# MSP430FR6972 register map
Registers are 16-bit, read-write, reset 0x0 unless marked. A register's access mark holds for its fields unless they carry their own. Offsets are from the block's base; [hi:lo] are bit positions; {n}, {i} and the like mark numbered series.

## USCI_A0_SPI_MODE
Base 0x000005C0
0x00 UCA0CTL1_SPI 8-bit — USCI A0 Control Register 1
0x01 UCA0CTL0_SPI 8-bit — USCI A0 Control Register 0
0x06 UCA0BR0_SPI 8-bit — USCI A0 Baud Rate 0
0x07 UCA0BR1_SPI 8-bit — USCI A0 Baud Rate 1
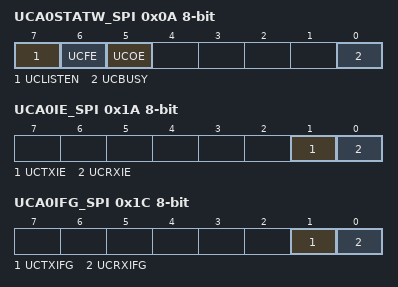
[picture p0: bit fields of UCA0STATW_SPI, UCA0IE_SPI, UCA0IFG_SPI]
0x0A UCA0STATW_SPI 8-bit — USCI A0 Status Register
  [7] UCLISTEN — USCI Listen mode
  [6] UCFE — USCI Frame Error Flag
  [5] UCOE — USCI Overrun Error Flag
  [0] UCBUSY — USCI Busy Flag
0x0C UCA0RXBUF_SPI — USCI A0 Receive Buffer
0x0E UCA0TXBUF_SPI — USCI A0 Transmit Buffer
0x1A UCA0IE_SPI 8-bit — USCI A0 Interrupt Enable Register
  [1] UCTXIE — USCI Transmit Interrupt Enable
  [0] UCRXIE — USCI Receive Interrupt Enable
0x1C UCA0IFG_SPI 8-bit — USCI A0 Interrupt Flags Register
  [1] UCTXIFG — SPI Transmit Interrupt Flag
  [0] UCRXIFG — SPI Receive Interrupt Flag
0x1E UCA0IV_SPI — USCI A0 Interrupt Vector Register

## USCI_A1_UART_MODE
Base 0x000005E0
0x00 UCA1CTL1 8-bit — USCI A1 Control Register 1
0x01 UCA1CTL0 8-bit — USCI A1 Control Register 0
0x02 UCA1CTLW1 — USCI A1 Control Word Register 1
  [1:0] UCGLIT — USCI Deglitch Time Bit 1
    {v}=USCI Deglitch time: {v} (v=0..3)
0x06 UCA1BR0 8-bit — USCI A1 Baud Rate 0
0x07 UCA1BR1 8-bit — USCI A1 Baud Rate 1
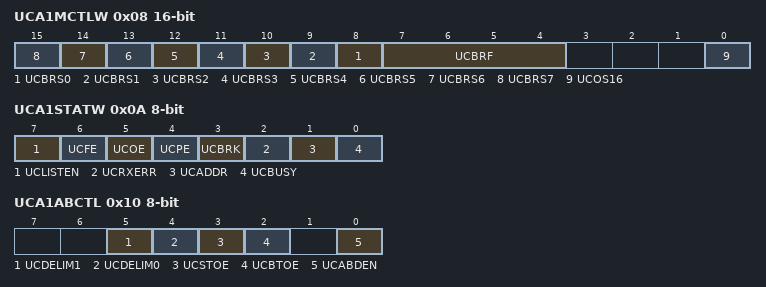
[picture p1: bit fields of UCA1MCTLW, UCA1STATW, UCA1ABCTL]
0x08 UCA1MCTLW — USCI A1 Modulation Control
  [n+8] UCBRS{n} (n=0..7) — USCI Second Stage Modulation Select {n}
  [7:4] UCBRF — USCI First Stage Modulation Select 3
    {v}=USCI First Stage Modulation: {v} (v=0..9); 10=USCI First Stage Modulation: A; 11=USCI First Stage Modulation: B; 12=USCI First Stage Modulation: C; 13=USCI First Stage Modulation: D; 14=USCI First Stage Modulation: E; 15=USCI First Stage Modulation: F
  [0] UCOS16 — USCI 16-times Oversampling enable
0x0A UCA1STATW 8-bit — USCI A1 Status Register
  [7] UCLISTEN — USCI Listen mode
  [6] UCFE — USCI Frame Error Flag
  [5] UCOE — USCI Overrun Error Flag
  [4] UCPE — USCI Parity Error Flag
  [3] UCBRK — USCI Break received
  [2] UCRXERR — USCI RX Error Flag
  [1] UCADDR — USCI Address received Flag
  [0] UCBUSY — USCI Busy Flag
0x0C UCA1RXBUF — USCI A1 Receive Buffer
0x0E UCA1TXBUF — USCI A1 Transmit Buffer
0x10 UCA1ABCTL 8-bit — USCI A1 LIN Control
  [5] UCDELIM1 — Break Sync Delimiter 1
  [4] UCDELIM0 — Break Sync Delimiter 0
  [3] UCSTOE — Sync-Field Timeout error
  [2] UCBTOE — Break Timeout error
  [0] UCABDEN — Auto Baud Rate detect enable
0x12 UCA1IRTCTL 8-bit — USCI A1 IrDA Transmit Control
0x13 UCA1IRRCTL 8-bit — USCI A1 IrDA Receive Control
0x1A UCA1IE — USCI A1 Interrupt Enable Register
0x1C UCA1IFG — USCI A1 Interrupt Flag Register
0x1E UCA1IV — USCI A1 Interrupt Vector Register

## USCI_A1_SPI_MODE
Base 0x000005E0
0x00 UCA1CTL1_SPI 8-bit — USCI A1 Control Register 1
0x01 UCA1CTL0_SPI 8-bit — USCI A1 Control Register 0
0x06 UCA1BR0_SPI 8-bit — USCI A1 Baud Rate 0
0x07 UCA1BR1_SPI 8-bit — USCI A1 Baud Rate 1
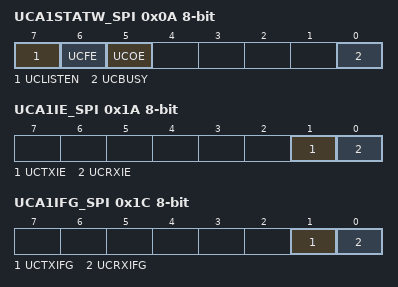
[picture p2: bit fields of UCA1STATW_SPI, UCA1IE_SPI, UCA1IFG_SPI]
0x0A UCA1STATW_SPI 8-bit — USCI A1 Status Register
  [7] UCLISTEN — USCI Listen mode
  [6] UCFE — USCI Frame Error Flag
  [5] UCOE — USCI Overrun Error Flag
  [0] UCBUSY — USCI Busy Flag
0x0C UCA1RXBUF_SPI — USCI A1 Receive Buffer
0x0E UCA1TXBUF_SPI — USCI A1 Transmit Buffer
0x1A UCA1IE_SPI 8-bit — USCI A1 Interrupt Enable Register
  [1] UCTXIE — USCI Transmit Interrupt Enable
  [0] UCRXIE — USCI Receive Interrupt Enable
0x1C UCA1IFG_SPI 8-bit — USCI A1 Interrupt Flags Register
  [1] UCTXIFG — SPI Transmit Interrupt Flag
  [0] UCRXIFG — SPI Receive Interrupt Flag
0x1E UCA1IV_SPI — USCI A1 Interrupt Vector Register

## USCI_B0_I2C_MODE
Base 0x00000640
0x00 UCB0CTL1 8-bit — USCI B0 Control Register 1
0x01 UCB0CTL0 8-bit — USCI B0 Control Register 0
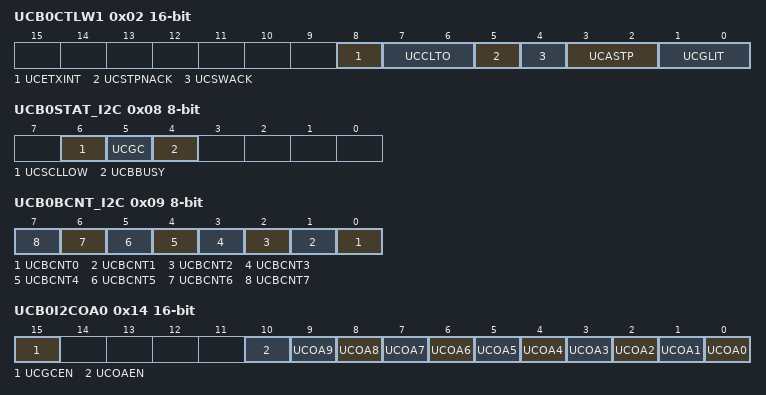
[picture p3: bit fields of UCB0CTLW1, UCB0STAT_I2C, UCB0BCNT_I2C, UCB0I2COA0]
0x02 UCB0CTLW1 — USCI B0 Control Word Register 1
  [8] UCETXINT — USCI Early UCTXIFG0
  [7:6] UCCLTO — USCI Clock low timeout Bit: 1
    {v}=USCI Clock low timeout: {v} (v=0..3)
  [5] UCSTPNACK — USCI Acknowledge Stop last byte
  [4] UCSWACK — USCI Software controlled ACK
  [3:2] UCASTP — USCI Automatic Stop condition generation Bit: 1
    {v}=USCI Automatic Stop condition generation: {v} (v=0..3)
  [1:0] UCGLIT — USCI Deglitch time Bit: 1
    {v}=USCI Deglitch time: {v} (v=0..3)
0x06 UCB0BR0 8-bit — USCI B0 Baud Rate 0
0x07 UCB0BR1 8-bit — USCI B0 Baud Rate 1
0x08 UCB0STAT_I2C 8-bit — USCI B0 Status Register
  [6] UCSCLLOW — SCL low
  [5] UCGC — General Call address received Flag
  [4] UCBBUSY — Bus Busy Flag
0x09 UCB0BCNT_I2C 8-bit — USCI B0 Byte Counter Register
  [n] UCBCNT{n} (n=0..7) — USCI Byte Counter Bit {n}
0x0A UCB0TBCNT — USCI B0 Byte Counter Threshold Register
0x0C UCB0RXBUF — USCI B0 Receive Buffer
0x0E UCB0TXBUF — USCI B0 Transmit Buffer
0x14 UCB0I2COA0 — USCI B0 I2C Own Address 0
  [15] UCGCEN — I2C General Call enable
  [10] UCOAEN — I2C Own Address enable
  [n] UCOA{n} (n=0..9) — I2C Own Address Bit {n}
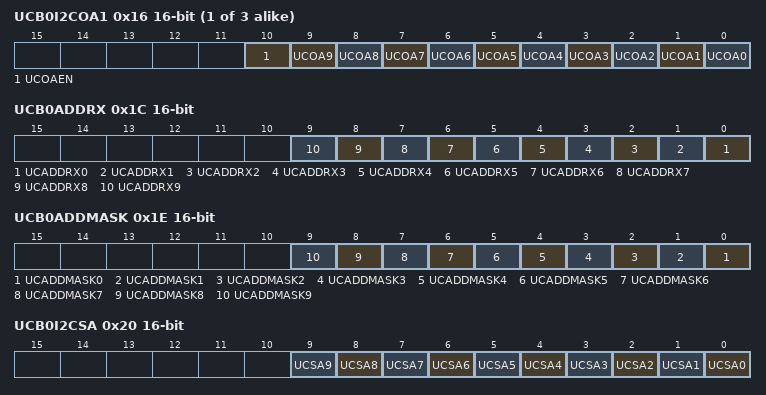
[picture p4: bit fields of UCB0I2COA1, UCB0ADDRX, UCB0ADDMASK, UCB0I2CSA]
{0x14+2i} UCB0I2COA{i} (i=1..3) — USCI B0 I2C Own Address {i}
  [10] UCOAEN — I2C Own Address enable
  [n] UCOA{n} (n=0..9) — I2C Own Address Bit {n}
0x1C UCB0ADDRX — USCI B0 Received Address Register
  [n] UCADDRX{n} (n=0..9) — I2C Receive Address Bit {n}
0x1E UCB0ADDMASK — USCI B0 Address Mask Register
  [n] UCADDMASK{n} (n=0..9) — I2C Address Mask Bit {n}
0x20 UCB0I2CSA — USCI B0 I2C Slave Address
  [n] UCSA{n} (n=0..9) — I2C Slave Address Bit {n}
0x2A UCB0IE — USCI B0 Interrupt Enable Register
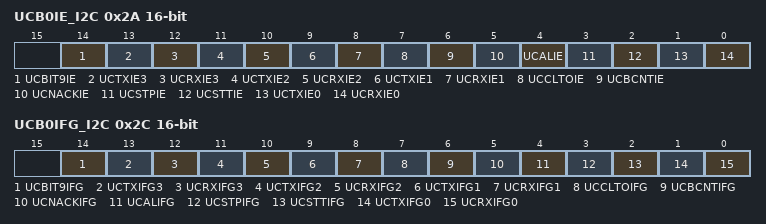
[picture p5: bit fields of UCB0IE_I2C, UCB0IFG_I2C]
0x2A UCB0IE_I2C (alternate view of UCB0IE) — USCI B0 Interrupt Enable Register
  [14] UCBIT9IE — I2C Bit 9 Position Interrupt Enable 3
  [13] UCTXIE3 — I2C Transmit Interrupt Enable 3
  [12] UCRXIE3 — I2C Receive Interrupt Enable 3
  [11] UCTXIE2 — I2C Transmit Interrupt Enable 2
  [10] UCRXIE2 — I2C Receive Interrupt Enable 2
  [9] UCTXIE1 — I2C Transmit Interrupt Enable 1
  [8] UCRXIE1 — I2C Receive Interrupt Enable 1
  [7] UCCLTOIE — I2C Clock Low Timeout interrupt enable
  [6] UCBCNTIE — I2C Automatic stop assertion interrupt enable
  [5] UCNACKIE — I2C NACK Condition interrupt enable
  [4] UCALIE — I2C Arbitration Lost interrupt enable
  [3] UCSTPIE — I2C STOP Condition interrupt enable
  [2] UCSTTIE — I2C START Condition interrupt enable
  [1] UCTXIE0 — I2C Transmit Interrupt Enable 0
  [0] UCRXIE0 — I2C Receive Interrupt Enable 0
0x2C UCB0IFG — USCI B0 Interrupt Flags Register
0x2C UCB0IFG_I2C (alternate view of UCB0IFG) — USCI B0 Interrupt Flags Register
  [14] UCBIT9IFG — I2C Bit 9 Possition Interrupt Flag 3
  [13] UCTXIFG3 — I2C Transmit Interrupt Flag 3
  [12] UCRXIFG3 — I2C Receive Interrupt Flag 3
  [11] UCTXIFG2 — I2C Transmit Interrupt Flag 2
  [10] UCRXIFG2 — I2C Receive Interrupt Flag 2
  [9] UCTXIFG1 — I2C Transmit Interrupt Flag 1
  [8] UCRXIFG1 — I2C Receive Interrupt Flag 1
  [7] UCCLTOIFG — I2C Clock low Timeout interrupt Flag
  [6] UCBCNTIFG — I2C Byte counter interrupt flag
  [5] UCNACKIFG — I2C NACK Condition interrupt Flag
  [4] UCALIFG — I2C Arbitration Lost interrupt Flag
  [3] UCSTPIFG — I2C STOP Condition interrupt Flag
  [2] UCSTTIFG — I2C START Condition interrupt Flag
  [1] UCTXIFG0 — I2C Transmit Interrupt Flag 0
  [0] UCRXIFG0 — I2C Receive Interrupt Flag 0
0x2E UCB0IV — USCI B0 Interrupt Vector Register
